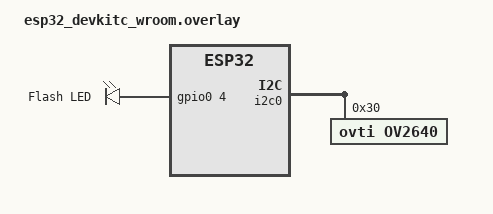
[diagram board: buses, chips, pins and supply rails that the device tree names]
/ {
   leds {
    compatible="gpio-leds";
    led_flash: led_flash {
        gpios = <&gpio0 4 GPIO_ACTIVE_HIGH>;
        label = "Flash LED";
        };
    };

    aliases {
        led0 = &led_flash;
    };
};

&i2c0 {
    ov2640: ov2640@30 {
        compatible = "ovti,ov2640";
        reg = < 0x30 >;
        status = "okay";
        clock-rate-control = < 0x80 >;
    };
};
